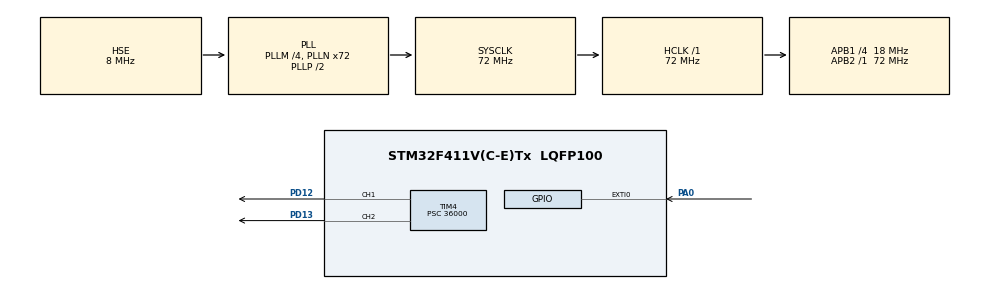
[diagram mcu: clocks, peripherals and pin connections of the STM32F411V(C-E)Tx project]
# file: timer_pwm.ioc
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Mcu.Family=STM32F4
Mcu.Name=STM32F411V(C-E)Tx
Mcu.Package=LQFP100
NVIC.EXTI0_IRQn=true\:3\:0\:true\:false\:true\:true\:true\:true
NVIC.PriorityGroup=NVIC_PRIORITYGROUP_4
NVIC.TIM4_IRQn=true\:4\:0\:true\:false\:true\:true\:true\:true
PA0-WKUP.Signal=GPXTI0
PD12.Signal=S_TIM4_CH1
PD13.Signal=S_TIM4_CH2
PH0\ -\ OSC_IN.Mode=HSE-External-Oscillator
PH0\ -\ OSC_IN.Signal=RCC_OSC_IN
PH1\ -\ OSC_OUT.Mode=HSE-External-Oscillator
PH1\ -\ OSC_OUT.Signal=RCC_OSC_OUT
ProjectManager.HeapSize=0x200
ProjectManager.StackSize=0x400
ProjectManager.TargetToolchain=STM32CubeIDE
RCC.48MHZClocksFreq_Value=36000000
RCC.AHBFreq_Value=72000000
RCC.APB1CLKDivider=RCC_HCLK_DIV4
RCC.APB1Freq_Value=18000000
RCC.APB1TimFreq_Value=36000000
RCC.APB2Freq_Value=72000000
RCC.APB2TimFreq_Value=72000000
RCC.CortexFreq_Value=72000000
RCC.HCLKFreq_Value=72000000
RCC.HSE_VALUE=8000000
RCC.HSI_VALUE=16000000
RCC.LSE_VALUE=32768
RCC.PLLM=4
RCC.PLLN=72
RCC.PLLSourceVirtual=RCC_PLLSOURCE_HSE
RCC.SYSCLKFreq_VALUE=72000000
RCC.SYSCLKSource=RCC_SYSCLKSOURCE_PLLCLK
RCC.VCOOutputFreq_Value=144000000
SH.S_TIM4_CH1.0=TIM4_CH1,Output Compare1 CH1
SH.S_TIM4_CH2.0=TIM4_CH2,PWM Generation2 CH2
TIM4.AutoReloadPreload=TIM_AUTORELOAD_PRELOAD_ENABLE
TIM4.Channel-Output\ Compare1\ CH1=TIM_CHANNEL_1
TIM4.Channel-PWM\ Generation2\ CH2=TIM_CHANNEL_2
TIM4.OC1Preload=ENABLE
TIM4.OCMode_1=TIM_OCMODE_TOGGLE
TIM4.Period=499
TIM4.Prescaler=36000
TIM4.Pulse-Output\ Compare1\ CH1=249
TIM4.Pulse-PWM\ Generation2\ CH2=149
VP_TIM4_VS_ClockSourceINT.Mode=Internal
board=custom

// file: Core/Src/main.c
/* USER CODE BEGIN Header */
/**
  ******************************************************************************
  * @file           : main.c
  * @brief          : Main program body
  ******************************************************************************
  * @attention
  *
  * Copyright (c) 2023 STMicroelectronics.
  * All rights reserved.
  *
  * This software is licensed under terms that can be found in the LICENSE file
  * in the root directory of this software component.
  * If no LICENSE file comes with this software, it is provided AS-IS.
  *
  ******************************************************************************
  */
/* USER CODE END Header */
#include "main.h"
#include "tim.h"
#include "gpio.h"

/* USER CODE BEGIN PV */
extern volatile  uint32_t pressed_counter ;

/* USER CODE END PV */

void SystemClock_Config(void);

int main(void)
{

  /* MCU Configuration--------------------------------------------------------*/

  /* Reset of all peripherals, Initializes the Flash interface and the Systick. */
  HAL_Init();

  /* Configure the system clock */
  SystemClock_Config();

  /* Initialize all configured peripherals */
  MX_GPIO_Init();
  MX_TIM4_Init();
  /* USER CODE BEGIN 2 */
#if 1
  start_timer_compare();
  start_timer_PWM();
  Start_Counting_Timer();

#endif
  /* USER CODE END 2 */

  /* Infinite loop */
  while (1)
  {

  }
}

void SystemClock_Config(void)
{
  RCC_OscInitTypeDef RCC_OscInitStruct = {0};
  RCC_ClkInitTypeDef RCC_ClkInitStruct = {0};

  /** Configure the main internal regulator output voltage
  */
  __HAL_RCC_PWR_CLK_ENABLE();
  __HAL_PWR_VOLTAGESCALING_CONFIG(PWR_REGULATOR_VOLTAGE_SCALE1);

  /** Initializes the RCC Oscillators according to the specified parameters
  * in the RCC_OscInitTypeDef structure.
  */
  RCC_OscInitStruct.OscillatorType = RCC_OSCILLATORTYPE_HSE;
  RCC_OscInitStruct.HSEState = RCC_HSE_ON;
  RCC_OscInitStruct.PLL.PLLState = RCC_PLL_ON;
  RCC_OscInitStruct.PLL.PLLSource = RCC_PLLSOURCE_HSE;
  RCC_OscInitStruct.PLL.PLLM = 4;
  RCC_OscInitStruct.PLL.PLLN = 72;
  RCC_OscInitStruct.PLL.PLLP = RCC_PLLP_DIV2;
  RCC_OscInitStruct.PLL.PLLQ = 4;
  if (HAL_RCC_OscConfig(&RCC_OscInitStruct) != HAL_OK)
  {
    Error_Handler();
  }

  /** Initializes the CPU, AHB and APB buses clocks
  */
  RCC_ClkInitStruct.ClockType = RCC_CLOCKTYPE_HCLK|RCC_CLOCKTYPE_SYSCLK
                              |RCC_CLOCKTYPE_PCLK1|RCC_CLOCKTYPE_PCLK2;
  RCC_ClkInitStruct.SYSCLKSource = RCC_SYSCLKSOURCE_PLLCLK;
  RCC_ClkInitStruct.AHBCLKDivider = RCC_SYSCLK_DIV1;
  RCC_ClkInitStruct.APB1CLKDivider = RCC_HCLK_DIV4;
  RCC_ClkInitStruct.APB2CLKDivider = RCC_HCLK_DIV1;

  if (HAL_RCC_ClockConfig(&RCC_ClkInitStruct, FLASH_LATENCY_2) != HAL_OK)
  {
    Error_Handler();
  }
}

void Error_Handler(void)
{
  __disable_irq();
  while (1)
  {
  }
}
